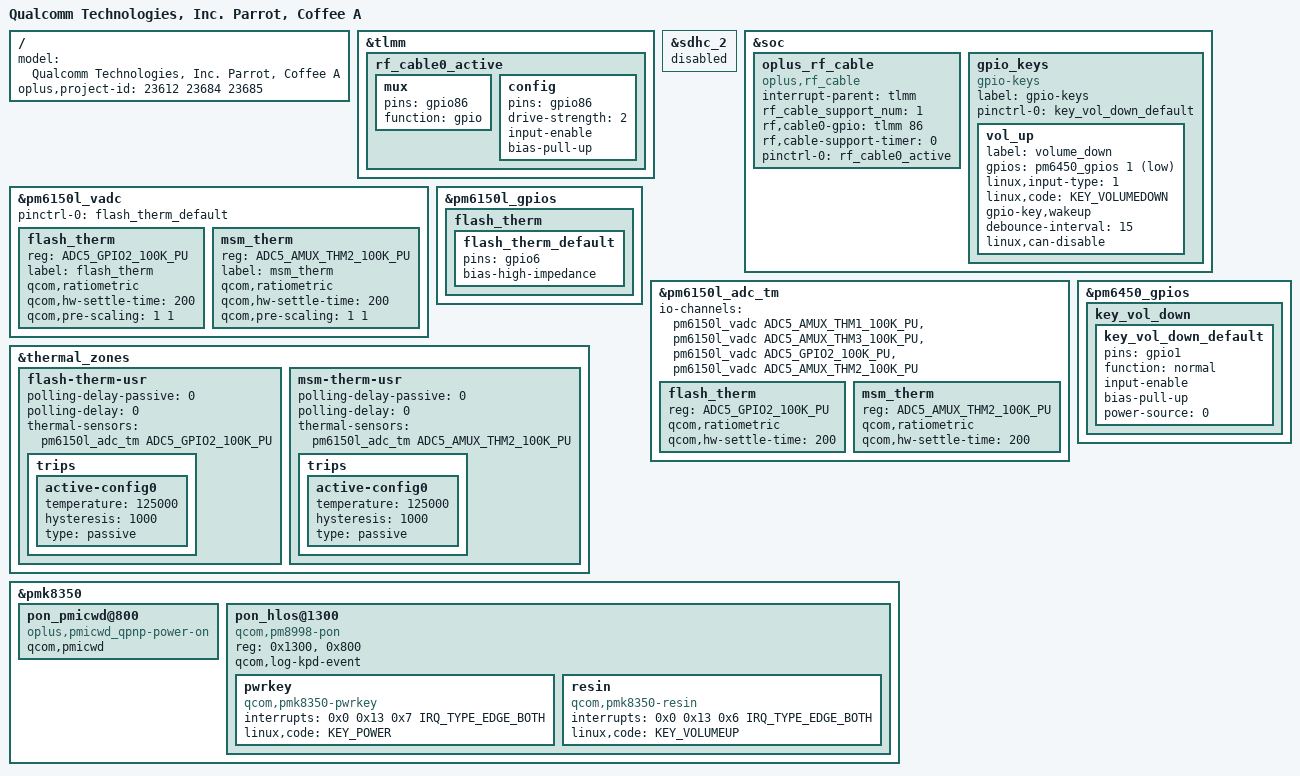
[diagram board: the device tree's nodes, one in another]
/dts-v1/;
/plugin/;
#include <dt-bindings/oplus/hw-id.h>
#include "../qcom/parrot-qrd-wcn6750-overlay.dts"
#include "parrot_overlay_common.dtsi"
#include "coffeea_23612_overlay_common.dtsi"
#include "oplus_uff/oplus_uff_23611.dtsi"
#include "oplus_chg/oplus-chg-23612.dtsi"
//#include "nfc/senna-nfc-sn110t.dtsi"
#include "sensor/coffee-oplus-sensor.dtsi"
#include "oplus_vibrator/oplus-vib-coffee.dtsi"
#include "nfc/coffee-nfc-sn220.dtsi"
/ {
	model = "Qualcomm Technologies, Inc. Parrot, Coffee A";
        oplus,project-id = <23612 23684 23685>;
        //oplus,hw-id = <OPLUS_EVB1 OPLUS_T0 OPLUS_EVT1 OPLUS_EVT2 OPLUS_DVT1 OPLUS_PVT1 OPLUS_MP1>;
};

&tlmm {
  rf_cable0_active: rf_cable0_active {
    mux {
      pins = "gpio86";
      function = "gpio";
    };
    config {
      pins = "gpio86";
      drive-strength = <2>;
      input-enable;
      bias-pull-up;
    };
  };
};

&sdhc_2 {
	status = "disabled";
};

&soc {
  oplus_rf_cable {
    compatible = "oplus,rf_cable";
    interrupt-parent = <&tlmm>;
    rf_cable_support_num = <1>;
    rf,cable0-gpio = <&tlmm 86 0>;
    rf,cable-support-timer = <0>;
    pinctrl-names = "rf_cable_active";
    pinctrl-0 = <&rf_cable0_active>;
  };
};

&pm6150l_vadc {
	/delete-property/ pinctrl-0;
	pinctrl-0 = <&flash_therm_default>;

	/delete-node/ ufs_therm;
	/delete-node/ wide_rfc_therm;
	flash_therm {
		reg = <ADC5_GPIO2_100K_PU>;
		label = "flash_therm";
		qcom,ratiometric;
		qcom,hw-settle-time = <200>;
		qcom,pre-scaling = <1 1>;
	};

	msm_therm {
		reg = <ADC5_AMUX_THM2_100K_PU>;
		label = "msm_therm";
		qcom,ratiometric;
		qcom,hw-settle-time = <200>;
		qcom,pre-scaling = <1 1>;
	};
};

&pm6150l_gpios {
	flash_therm {
		flash_therm_default: flash_therm_default {
			pins = "gpio6";
			bias-high-impedance;
		};
	};
};

&pm6150l_adc_tm {
	/delete-property/ io-channels;
	io-channels = <&pm6150l_vadc ADC5_AMUX_THM1_100K_PU>,
			<&pm6150l_vadc ADC5_AMUX_THM3_100K_PU>,
			<&pm6150l_vadc ADC5_GPIO2_100K_PU>,
			<&pm6150l_vadc ADC5_AMUX_THM2_100K_PU>;

	/delete-node/ ufs_therm;
	/delete-node/ wide_rfc_therm;
	flash_therm {
		reg = <ADC5_GPIO2_100K_PU>;
		qcom,ratiometric;
		qcom,hw-settle-time = <200>;
	};

	msm_therm {
		reg = <ADC5_AMUX_THM2_100K_PU>;
		qcom,ratiometric;
		qcom,hw-settle-time = <200>;
	};
};

&thermal_zones {
	/delete-node/ sys-therm-1;
	/delete-node/ sys-therm-2;
	flash-therm-usr {
		polling-delay-passive = <0>;
		polling-delay = <0>;
		thermal-sensors = <&pm6150l_adc_tm ADC5_GPIO2_100K_PU>;
		trips {
			active-config0 {
				temperature = <125000>;
				hysteresis = <1000>;
				type = "passive";
			};
		};
	};

	msm-therm-usr {
		polling-delay-passive = <0>;
		polling-delay = <0>;
		thermal-sensors = <&pm6150l_adc_tm ADC5_AMUX_THM2_100K_PU>;
		trips {
			active-config0 {
				temperature = <125000>;
				hysteresis = <1000>;
				type = "passive";
			};
		};
	};
};

//gujiayin@BSP.charge add for vol key start
&pmk8350 {
	/delete-node/ pon_hlos@1300;

	pon_pmicwd@800 {
		compatible = "oplus,pmicwd_qpnp-power-on";
		qcom,pmicwd;
	};

	pon_hlos@1300 {
		compatible = "qcom,pm8998-pon";
		reg = <0x1300>, <0x800>;
		reg-names = "pon_hlos", "pon_pbs";
		qcom,log-kpd-event;

		pwrkey {
			compatible = "qcom,pmk8350-pwrkey";
			interrupts = <0x0 0x13 0x7 IRQ_TYPE_EDGE_BOTH>;
			linux,code = <KEY_POWER>;
		};

		resin {
			compatible = "qcom,pmk8350-resin";
			interrupts = <0x0 0x13 0x6 IRQ_TYPE_EDGE_BOTH>;
			linux,code = <KEY_VOLUMEUP>;
		};
	};
};

&pm6450_gpios {
	key_vol_down {
		key_vol_down_default: key_vol_down_default {
			pins = "gpio1";
			function = "normal";
			input-enable;
			bias-pull-up;
			power-source = <0>;
		};
	};
};

&soc {
	gpio_keys {
		compatible = "gpio-keys";
		label = "gpio-keys";

		pinctrl-names = "default";
		pinctrl-0 = <&key_vol_down_default>;

		vol_up {
			label = "volume_down";
			gpios = <&pm6450_gpios 1 GPIO_ACTIVE_LOW>;
			linux,input-type = <1>;
			linux,code = <KEY_VOLUMEDOWN>;
			gpio-key,wakeup;
			debounce-interval = <15>;
			linux,can-disable;
		};
	};
};
//gujiayin@BSP.charge add for vol key end
